AUTOSAR XML (schema 4-0-3)
standard types defined: Boolean, UInt16, UInt32, UInt8
package /AUTOSAR_Platform/DataConstrs
  range DC_Boolean: raw 0..1
  range DC_UInt16: raw 0..65535
  range DC_UInt8: raw 0..255
package /PATAC/MSM/ComponentTypes
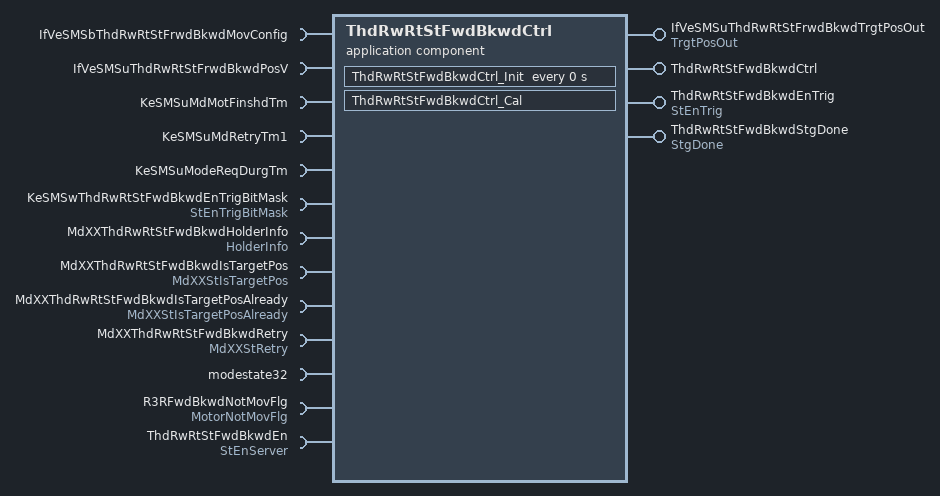
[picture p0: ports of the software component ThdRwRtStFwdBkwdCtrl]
  application sw component type ThdRwRtStFwdBkwdCtrl
    4 x provide port:
      IfVeSMSuThdRwRtStFrwdBkwdTrgtPosOut: nonqueued-sender-com-spec{data-element=TrgtPosOut/Val, init-value=0}, provided-interface=TrgtPosOut
      ThdRwRtStFwdBkwdCtrl: server-com-spec{operation=Cal, queue-length=1}, provided-interface=ThdRwRtStFwdBkwdCtrl
      ThdRwRtStFwdBkwdEnTrig: nonqueued-sender-com-spec{data-element=StEnTrig/Val, init-value=0}, provided-interface=StEnTrig
      ThdRwRtStFwdBkwdStgDone: nonqueued-sender-com-spec{data-element=StgDone/Val, init-value=0}, provided-interface=StgDone
    13 x require port:
      IfVeSMSbThdRwRtStFrwdBkwdMovConfig: nonqueued-receiver-com-spec{data-element=IfVeSMSbThdRwRtStFrwdBkwdMovConfig/Val, filter=data-filter-type=ALWAYS, init-value=0}, required-interface=IfVeSMSbThdRwRtStFrwdBkwdMovConfig
      IfVeSMSuThdRwRtStFrwdBkwdPosV: nonqueued-receiver-com-spec{data-element=IfVeSMSuThdRwRtStFrwdBkwdPosV/Val, filter=data-filter-type=ALWAYS, init-value=0}, required-interface=IfVeSMSuThdRwRtStFrwdBkwdPosV
      KeSMSuMdMotFinshdTm: parameter-require-com-spec{init-value=0, parameter=KeSMSuMdMotFinshdTm/Val}, required-interface=KeSMSuMdMotFinshdTm
      KeSMSuMdRetryTm1: parameter-require-com-spec{init-value=0, parameter=KeSMSuMdRetryTm1/Val}, required-interface=KeSMSuMdRetryTm1
      KeSMSuModeReqDurgTm: parameter-require-com-spec{init-value=0, parameter=KeSMSuModeReqDurgTm/Val}, required-interface=KeSMSuModeReqDurgTm
      KeSMSwThdRwRtStFwdBkwdEnTrigBitMask: parameter-require-com-spec{init-value=6153, parameter=StEnTrigBitMask/Val}, required-interface=StEnTrigBitMask
      MdXXThdRwRtStFwdBkwdHolderInfo: nonqueued-receiver-com-spec{data-element=HolderInfo/Val, filter=data-filter-type=ALWAYS, init-value=0}, required-interface=HolderInfo
      MdXXThdRwRtStFwdBkwdIsTargetPos: nonqueued-receiver-com-spec{data-element=MdXXStIsTargetPos/Val, filter=data-filter-type=ALWAYS, init-value=0}, required-interface=MdXXStIsTargetPos
      MdXXThdRwRtStFwdBkwdIsTargetPosAlready: nonqueued-receiver-com-spec{data-element=MdXXStIsTargetPosAlready/Val, filter=data-filter-type=ALWAYS, init-value=0}, required-interface=MdXXStIsTargetPosAlready
      MdXXThdRwRtStFwdBkwdRetry: nonqueued-receiver-com-spec{data-element=MdXXStRetry/Val, filter=data-filter-type=ALWAYS, init-value=0}, required-interface=MdXXStRetry
      modestate32: nonqueued-receiver-com-spec{data-element=modestate32/Val, filter=data-filter-type=ALWAYS, init-value=0}, required-interface=modestate32
      R3RFwdBkwdNotMovFlg: nonqueued-receiver-com-spec{data-element=MotorNotMovFlg/Val, filter=data-filter-type=ALWAYS, init-value=0}, required-interface=MotorNotMovFlg
      ThdRwRtStFwdBkwdEn: required-com-specs=[Clear, Get, Set], required-interface=StEnServer
    behavior ThdRwRtStFwdBkwdCtrl_InternalBehavior
      operation invoked event OIT_ThdRwRtStFwdBkwdCtrl_Cal_ThdRwRtStFwdBkwdCtrl_Cal: start-on-event=ThdRwRtStFwdBkwdCtrl_Cal, operation=ThdRwRtStFwdBkwdCtrl.Cal
      timing event ThdRwRtStFwdBkwdCtrl_InitEvent: start-on-event=ThdRwRtStFwdBkwdCtrl_Init, period=0
      runnable ThdRwRtStFwdBkwdCtrl_Cal
        data-receive-point-by-arguments:
          8 x access:
            REC_IfVeSMSbThdRwRtStFrwdBkwdMovConfig_Val: accessed-variable=IfVeSMSbThdRwRtStFrwdBkwdMovConfig.Val
            REC_IfVeSMSuThdRwRtStFrwdBkwdPosV_Val: accessed-variable=IfVeSMSuThdRwRtStFrwdBkwdPosV.Val
            REC_MdXXThdRwRtStFwdBkwdHolderInfo_Val: accessed-variable=MdXXThdRwRtStFwdBkwdHolderInfo.Val
            REC_MdXXThdRwRtStFwdBkwdIsTargetPos_Val: accessed-variable=MdXXThdRwRtStFwdBkwdIsTargetPos.Val
            REC_MdXXThdRwRtStFwdBkwdIsTargetPosAlready_Val: accessed-variable=MdXXThdRwRtStFwdBkwdIsTargetPosAlready.Val
            REC_MdXXThdRwRtStFwdBkwdRetry_Val: accessed-variable=MdXXThdRwRtStFwdBkwdRetry.Val
            REC_modestate32_Val: accessed-variable=modestate32.Val
            REC_R3RFwdBkwdNotMovFlg_Val: accessed-variable=R3RFwdBkwdNotMovFlg.Val
        data-send-points:
          access SEND_IfVeSMSuThdRwRtStFrwdBkwdTrgtPosOut_Val: accessed-variable=IfVeSMSuThdRwRtStFrwdBkwdTrgtPosOut.Val
          access SEND_ThdRwRtStFwdBkwdEnTrig_Val: accessed-variable=ThdRwRtStFwdBkwdEnTrig.Val
          access SEND_ThdRwRtStFwdBkwdStgDone_Val: accessed-variable=ThdRwRtStFwdBkwdStgDone.Val
        4 x parameter access:
          PA_KeSMSuMdMotFinshdTm_Val: accessed-parameter=KeSMSuMdMotFinshdTm.Val
          PA_KeSMSuMdRetryTm1_Val: accessed-parameter=KeSMSuMdRetryTm1.Val
          PA_KeSMSuModeReqDurgTm_Val: accessed-parameter=KeSMSuModeReqDurgTm.Val
          PA_KeSMSwThdRwRtStFwdBkwdEnTrigBitMask_Val: accessed-parameter=KeSMSwThdRwRtStFwdBkwdEnTrigBitMask.Val
        sync call SC_ThdRwRtStFwdBkwdEn_Get: operation=ThdRwRtStFwdBkwdEn.Get, timeout=0
      runnable ThdRwRtStFwdBkwdCtrl_Init
        4 x parameter access:
          PA_KeSMSuMdMotFinshdTm_Val: accessed-parameter=KeSMSuMdMotFinshdTm.Val
          PA_KeSMSuMdRetryTm1_Val: accessed-parameter=KeSMSuMdRetryTm1.Val
          PA_KeSMSuModeReqDurgTm_Val: accessed-parameter=KeSMSuModeReqDurgTm.Val
          PA_KeSMSwThdRwRtStFwdBkwdEnTrigBitMask_Val: accessed-parameter=KeSMSwThdRwRtStFwdBkwdEnTrigBitMask.Val
  swc implementation ThdRwRtStFwdBkwdCtrl_Implementation: behavior=ThdRwRtStFwdBkwdCtrl_InternalBehavior
    code-descriptors:
      code Default: artifact-descriptors=autosar-engineering-object={short-label=Default, category=SWSRC}
package /PATAC/MSM/ModeAdjust/CalPortInterface
  parameter interface KeSMSuMdMotFinshdTm
    parameter data prototype Val: sw-calibration-access=READ-WRITE, type=UInt16
  parameter interface KeSMSuModeReqDurgTm
    parameter data prototype Val: sw-calibration-access=READ-WRITE, type=UInt16
  parameter interface StEnTrigBitMask
    parameter data prototype Val: sw-calibration-access=READ-WRITE, type=UInt32
package /PATAC/MSM/ModeAdjust/Interfaces
  sender receiver interface IfVeSMSuThdRwRtStFrwdBkwdPosV: invalidation-policy{data-element=IfVeSMSuThdRwRtStFrwdBkwdPosV/Val, handle-invalid=DONT-INVALIDATE}
    data Val: type=Boolean
package /PATAC/MSM/ModeAdjust/PortInterface
  client server interface StEnServer
    operation Clear
      arg data: type=UInt8, direction=IN, server-argument-impl-policy=USE-ARGUMENT-TYPE
    operation Get
      arg data: type=UInt32, direction=OUT, server-argument-impl-policy=USE-ARGUMENT-TYPE
    operation Set
      arg data: type=UInt8, direction=IN, server-argument-impl-policy=USE-ARGUMENT-TYPE
  client server interface ThdRwRtStFwdBkwdCtrl
    operation Cal
  9 x sender receiver interface:
    HolderInfo: invalidation-policy{data-element=HolderInfo/Val, handle-invalid=DONT-INVALIDATE}
      data Val: type=UInt32
    MdXXStIsTargetPos: invalidation-policy{data-element=MdXXStIsTargetPos/Val, handle-invalid=DONT-INVALIDATE}
      data Val: type=UInt32
    MdXXStIsTargetPosAlready: invalidation-policy{data-element=MdXXStIsTargetPosAlready/Val, handle-invalid=DONT-INVALIDATE}
      data Val: type=UInt32
    MdXXStRetry: invalidation-policy{data-element=MdXXStRetry/Val, handle-invalid=DONT-INVALIDATE}
      data Val: type=UInt32
    modestate32: invalidation-policy{data-element=modestate32/Val, handle-invalid=DONT-INVALIDATE}
      data Val: type=UInt32
    MotorNotMovFlg: invalidation-policy{data-element=MotorNotMovFlg/Val, handle-invalid=DONT-INVALIDATE}
      data Val: type=Boolean
    StEnTrig: invalidation-policy{data-element=StEnTrig/Val, handle-invalid=DONT-INVALIDATE}
      data Val: type=Boolean
    StgDone: invalidation-policy{data-element=StgDone/Val, handle-invalid=DONT-INVALIDATE}
      data Val: type=Boolean
    TrgtPosOut: invalidation-policy{data-element=TrgtPosOut/Val, handle-invalid=DONT-INVALIDATE}
      data Val: type=Boolean
package /PATAC/MSM/PortInterfaces
  parameter interface KeSMSuMdRetryTm1
    parameter data prototype Val: sw-calibration-access=READ-WRITE, type=UInt8
  sender receiver interface IfVeSMSbThdRwRtStFrwdBkwdMovConfig: invalidation-policy{data-element=IfVeSMSbThdRwRtStFrwdBkwdMovConfig/Val, handle-invalid=DONT-INVALIDATE}
    data Val: type=Boolean
